# STM32H7P4xx register map
File version: 1.0
Registers are 32-bit, read-write, reset 0x0 unless marked. A register's access mark holds for its fields unless they carry their own. Offsets are from the block's base; [hi:lo] are bit positions; {n}, {i} and the like mark numbered series; 'fields as' and 'values as' point back to an identical list.

## FMC_NAND — Flexible Memory Controller NAND Bank3 configuration
Base 0x52004080
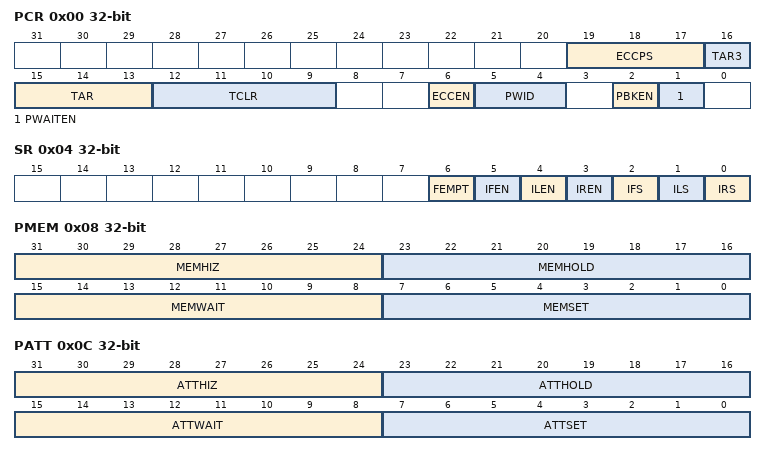
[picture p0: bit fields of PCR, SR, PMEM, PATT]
0x00 PCR — NAND flash control register
  [19:17] ECCPS — ECC page size
  [16] TAR3 — ALE to RE delay
  [15:13] TAR — ALE to RE delay
  [12:9] TCLR — CLE to RE delay
  [6] ECCEN — ECC computation logic enable bit
  [5:4] PWID — Data bus width
  [2] PBKEN — NAND flash memory bank enable bit
  [1] PWAITEN — Wait feature enable bit
0x04 SR ro — NAND Flash FIFO status and interrupt register
  [6] FEMPT — FIFO empty
  [5] IFEN
  [4] ILEN
  [3] IREN
  [2] IFS — Interrupt falling edge status
  [1] ILS — Interrupt high-level status
  [0] IRS — Interrupt rising edge status
0x08 PMEM — NAND Flash Common memory space timing register
  [31:24] MEMHIZ — Common memory x data bus Hi-Z time
  [23:16] MEMHOLD — Common memory hold time
  [15:8] MEMWAIT — Common memory wait time
  [7:0] MEMSET — Common memory x setup time
0x0C PATT — NAND Flash Attribute memory space timing register
  [31:24] ATTHIZ
  [23:16] ATTHOLD — Attribute memory hold time
  [15:8] ATTWAIT — Attribute memory wait time
  [7:0] ATTSET — Attribute memory setup time
0x14 ECCR ro — NAND Flash ECC result registers
  [31:0] ECC — ECC result

## FMC_SDRAM — Flexible Memory Controller SDRAM Bank1 and Bank2 configuration
Base 0x52004140
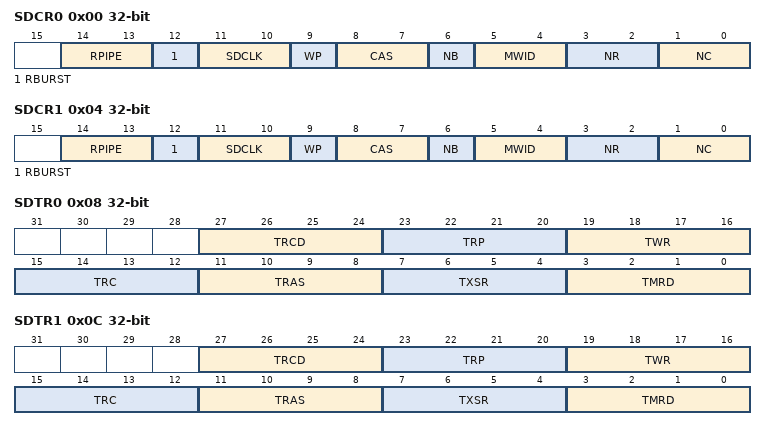
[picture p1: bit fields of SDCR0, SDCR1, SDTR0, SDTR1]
0x00 SDCR0 — FMC SDRAM device control register
  [14:13] RPIPE — Read pipe
  [12] RBURST — Burst read
  [11:10] SDCLK — SDRAM clock configuration
  [9] WP — Write protection
  [8:7] CAS — CAS Latency
  [6] NB — Number of internal banks
  [5:4] MWID — Memory data bus width
  [3:2] NR — Number of row address bits
  [1:0] NC — Number of column address bits
0x04 SDCR1 — FMC SDRAM device control register
  fields as SDCR0
0x08 SDTR0 — SDRAM Timing registers
  [27:24] TRCD — Row to column delay
  [23:20] TRP — Row precharge delay
  [19:16] TWR — Recovery delay
  [15:12] TRC — Row cycle delay
  [11:8] TRAS — Self refresh time
  [7:4] TXSR — Exit Self-refresh delay
  [3:0] TMRD — Load Mode Register to Active
0x0C SDTR1 — SDRAM Timing registers
  fields as SDTR0
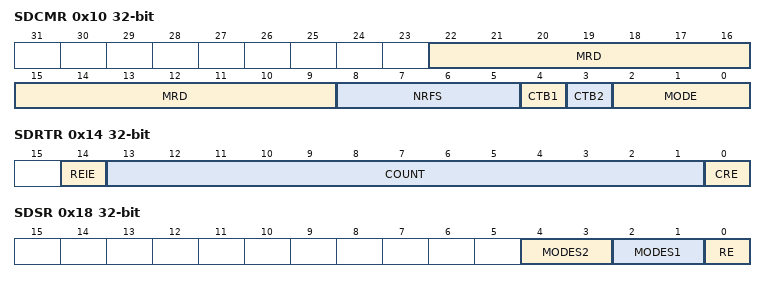
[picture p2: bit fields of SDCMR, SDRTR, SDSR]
0x10 SDCMR — SDRAM Command Mode register
  [22:9] MRD — Mode Register definition
  [8:5] NRFS — Number of Auto-refresh
  [4] CTB1 — Command Target Bank 1
  [3] CTB2 — Command Target Bank 2
  [2:0] MODE — Command mode
0x14 SDRTR — SDRAM Refresh Timer register
  [14] REIE — RES Interrupt Enable
  [13:1] COUNT — Refresh Timer Count
  [0] CRE — Clear Refresh error flag
0x18 SDSR ro — SDRAM Status register
  [4:3] MODES2 — Status Mode for Bank 2
  [2:1] MODES1 — Status Mode for Bank 1
  [0] RE — Refresh error flag

## DLYB_XSPI1 — Delay Block (DLYB)
Base 0x52006000
Same registers: DLYB_SDMMC1 0x52008000
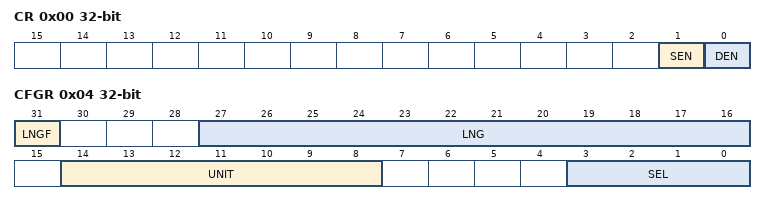
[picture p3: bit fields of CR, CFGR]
0x00 CR — DLYB control register
  [1] SEN — Sampler length enable bit
  [0] DEN — Delay block enable bit
0x04 CFGR — DLYB configuration register
  [31] LNGF — Length valid flag
  [27:16] LNG — Delay line length value
  [14:8] UNIT — Delay Defines the delay of a Unit delay cell
  [3:0] SEL — Select the phase for the Output clock

## RAMECC1 — RAM ECC monitoring (RAMECC)
Base 0x52009000
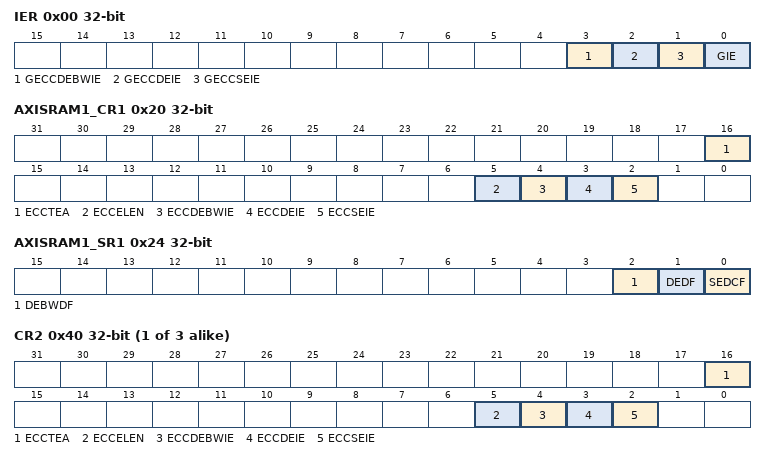
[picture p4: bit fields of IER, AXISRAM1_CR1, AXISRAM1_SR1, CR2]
0x00 IER — RAMECC interrupt enable register
  [3] GECCDEBWIE
  [2] GECCDEIE
  [1] GECCSEIE
  [0] GIE — Global interrupt enable
0x20 AXISRAM1_CR1 — RAMECC monitor configuration register
  [16] ECCTEA — ECC test ECC access
  [5] ECCELEN — ECC error latching enable
  [4] ECCDEBWIE
  [3] ECCDEIE — ECC double error interrupt enable
  [2] ECCSEIE — ECC single error interrupt enable
0x24 AXISRAM1_SR1 — RAMECC monitor status register
  [2] DEBWDF
  [1] DEDF — ECC double error detected flag
  [0] SEDCF
0x28 AXISRAM1_FAR1 ro — RAMECC monitor failing address register
  [31:0] FADD — ECC error failing address
0x2C AXISRAM1_FDR1 ro — RAMECC monitor failing data register
  [31:0] FDATA — Failing data
0x34 AXISRAM1_FECR1 ro — RAMECC monitor failing ECC error code register
  [31:0] FEC — Failing error code
{0x0+0x20*i} CR{i} (i=2..4) — RAMECC monitor configuration register
  fields as AXISRAM1_CR1
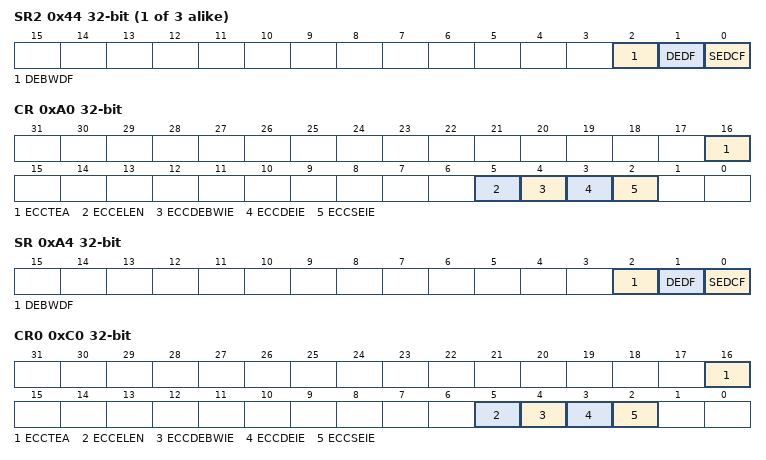
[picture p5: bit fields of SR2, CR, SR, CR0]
{0x4+0x20*i} SR{i} (i=2..4) — RAMECC monitor status register
  [2] DEBWDF
  [1] DEDF — ECC double error detected flag
  [0] SEDCF
{0x8+0x20*i} FAR{i} ro (i=2..4) — RAMECC monitor failing address register
  [31:0] FADD — ECC error failing address
{0xC+0x20*i} FDR{i} ro (i=2..4) — RAMECC monitor failing data register
  [31:0] FDATA — Failing data
{0x14+0x20*i} FECR{i} ro (i=2..4) — RAMECC monitor failing ECC error code register
  [31:0] FEC — Failing error code
0xA0 CR — RAMECC monitor configuration register
  fields as AXISRAM1_CR1
0xA4 SR — RAMECC monitor status register
  [2] DEBWDF
  [1] DEDF — ECC double error detected flag
  [0] SEDCF
0xA8 FAR ro — RAMECC monitor failing address register
  [31:0] FADD — ECC error failing address
0xAC FDR ro — RAMECC monitor failing data register
  [31:0] FDATA — Failing data
0xB4 FECR ro — RAMECC monitor failing ECC error code register
  [31:0] FEC — Failing error code
0xC0 CR0 — RAMECC monitor configuration register
  fields as AXISRAM1_CR1
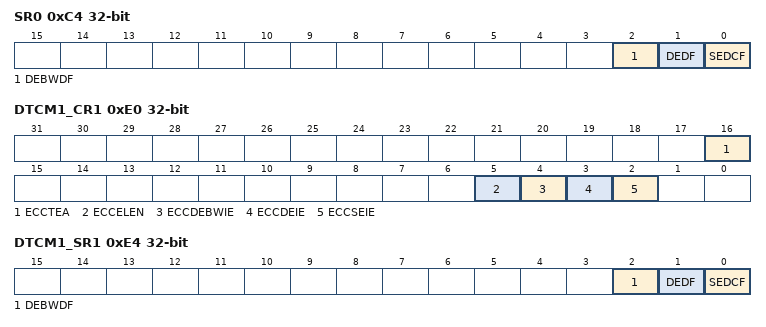
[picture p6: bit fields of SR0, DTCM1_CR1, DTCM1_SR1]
0xC4 SR0 — RAMECC monitor status register
  [2] DEBWDF
  [1] DEDF — ECC double error detected flag
  [0] SEDCF
0xC8 FAR0 ro — RAMECC monitor failing address register
  [31:0] FADD — ECC error failing address
0xCC FDR0 ro — RAMECC monitor failing data register
  [31:0] FDATA — Failing data
0xD4 FECR0 ro — RAMECC monitor failing ECC error code register
  [31:0] FEC — Failing error code
0xE0 DTCM1_CR1 — RAMECC monitor configuration register
  fields as AXISRAM1_CR1
0xE4 DTCM1_SR1 — RAMECC monitor status register
  [2] DEBWDF
  [1] DEDF — ECC double error detected flag
  [0] SEDCF
0xE8 DTCM1_FAR1 ro — RAMECC monitor failing address register
  [31:0] FADD — ECC error failing address
0xEC DTCM1_FDR1 ro — RAMECC monitor failing data register
  [31:0] FDATA — Failing data
0xF4 DTCM1_FECR1 ro — RAMECC monitor failing ECC error code register
  [31:0] FEC — Failing error code
